# ESP32S31_RADIO register map
Vendor: Espressif; Series: ESP32-S31; File version: 3.52
Registers are 32-bit, read-write, no defined reset value unless marked. A register's access mark holds for its fields unless they carry their own. Offsets are from the block's base; [hi:lo] are bit positions; {n}, {i} and the like mark numbered series; 'fields as' and 'values as' point back to an identical list.

## PHY_I2C_COMMAND_RAM — Official S31 reg_base.h names this aperture DR_REG_I2C_ANA_MST_MEM_BASE. The complete blob establishes its forty-five-entry command layout and the population order in phy_i2c_master_cmd_mem_init. Complete phy_i2c_check independently names ten logical banks, their block IDs, selected host and finite register-index ranges.
Base 0x2010FC00
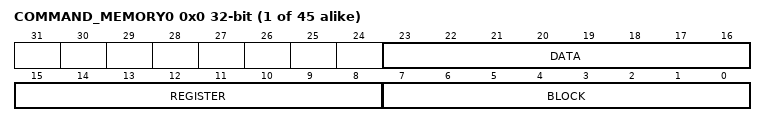
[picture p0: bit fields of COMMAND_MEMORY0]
{0x0+4i} COMMAND_MEMORY{i} (i=0..44) wo — Project-assigned name. One PHY-I2C master command-memory entry; the public header proves the containing memory aperture while the complete blob proves this word layout.
  [23:16] DATA — Project-assigned name.
  [15:8] REGISTER — Project-assigned name.
  [7:0] BLOCK — Project-assigned name. Logical PHY-I2C block ID. The bank host and valid half-open register-index ranges are: SAR1 host 0 [0,7), ULP host 1 [0,11), RFPLL host 1 [0,22), RFPLL_SDM host 1 [0,7), BBPLL host 0 [0,11), BBTOP host 1 [0,57), PERIF host 0 [0,13), BIAS host 1 [0,4), TXRF host 1 [1,22), DIG_REG host 0 [0,15).
    16=SAR1; 97=ULP; 98=RFPLL; 99=RFPLL_SDM; 102=BBPLL; 103=BBTOP; 105=PERIF; 106=BIAS; 107=TXRF; 109=DIG_REG

## WIFI_PHY_RATE_ORACLE — Wi-Fi-owned PHY words: the noise-floor measurement read by Wi-Fi link policy and the low-rate receive gate of Wi-Fi rate control and 11b long-range RX. Only Wi-Fi touches these words: no PHY registration, calibration or tracking body and no Bluetooth or IEEE 802.15.4 body accesses them, so they belong to the Wi-Fi partition rather than the shared radio PHY. They share the radio-core base with the PHY oracles.
Base 0x20100000
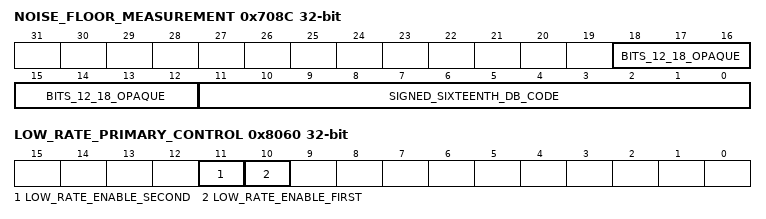
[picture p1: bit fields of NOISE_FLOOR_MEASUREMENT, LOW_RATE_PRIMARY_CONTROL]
0x708C NOISE_FLOOR_MEASUREMENT ro — Project-assigned name. Complete phy_read_hw_noisefloor reads this word once, sign-extends the low twelve-bit two's-complement value and divides it arithmetically by four to produce its quarter-dB result; it consumes no higher bits. The librftest saturation probes read bits 18:12. Open rev0 HIL read a stable -92 dBm whole-unit result through the complete ROM plus wDev transform.
  [18:12] BITS_12_18_OPAQUE — Opaque: meaning not established. Seven-bit receive status field. Complete librftest get_rfrx_sat counts how many of one hundred reads have the value 49 and returns that count as its RF receive saturation result; phy_rx_sat_test samples it after forcing receive gain. Neither body assigns a unit to the value.
  [11:0] SIGNED_SIXTEENTH_DB_CODE — Project-assigned name. Signed twelve-bit noise-floor measurement in sixteenth-dB units. The complete ROM arithmetic shift produces quarter-dB and libpp[wdev.o]::wDev_GetNoiseFloor applies rounded division by four once more before retaining a signed byte; open rev0 HIL observed -92 dBm.
0x8060 LOW_RATE_PRIMARY_CONTROL — Project-assigned name. Complete phy_enable_low_rate sets bits 10 and 11 through separate fresh-read RMW edges; complete phy_disable_low_rate clears them in the same order; complete phy_rx11blr_cfg replaces both with its caller low bit.
  [11] LOW_RATE_ENABLE_SECOND — Project-assigned name. Second independently updated low-rate enable bit.
  [10] LOW_RATE_ENABLE_FIRST — Project-assigned name. First independently updated low-rate enable bit.
0x807C LOW_RATE_SECONDARY_CONTROL — Project-assigned name. Third and final fresh-read RMW in the complete low-rate leaves and phy_rx11blr_cfg.
  [11] LOW_RATE_ENABLE — Project-assigned name. Set by complete phy_enable_low_rate and cleared by complete phy_disable_low_rate.

## PHY_IQ_ESTIMATOR_ORACLE — DC/IQ estimator configuration, signed result and activity registers recovered from complete S31 rev0 ROM bodies and the complete pinned phy_check_rx_sat blob leaf. Unknown electrical roles remain explicit.
Base 0x20100000
0x44C ESTIMATOR_CONFIG — Project-assigned name. Complete phy_iq_est_enable replaces bits 27:26 with encoding one before each measurement.
  [27:26] BITS_26_27_OPAQUE — Opaque: meaning not established. Two-bit field set to encoding one by phy_iq_est_enable.
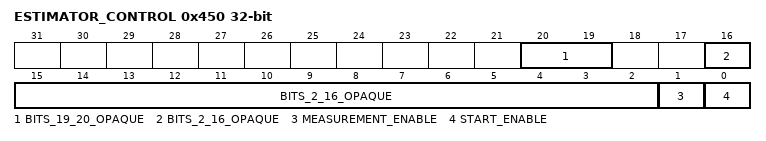
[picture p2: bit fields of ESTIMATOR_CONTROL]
0x450 ESTIMATOR_CONTROL — Project-assigned name. Complete phy_iq_est_enable publishes the caller control word and starts both measurement phases; complete phy_iq_est_disable clears them in reverse order around a one-microsecond delay.
  [20:19] BITS_19_20_OPAQUE — Opaque: meaning not established. Complete phy_iq_est_enable replaces the field with encoding two.
  [16:2] BITS_2_16_OPAQUE — Opaque: meaning not established. Fifteen-bit caller value shifted left by two.
  [1] MEASUREMENT_ENABLE — Project-assigned name.
  [0] START_ENABLE — Project-assigned name.
0x454 SIGNAL_POWER_SUM_I ro — Project-assigned name. Signed result consumed by complete phy_rxiq_get_mis and phy_get_rx_sig_pwr.
  [31:0] VALUE — Project-assigned name. Complete signed estimator result.
0x458 SIGNAL_POWER_DIFFERENCE_I ro — Project-assigned name. Signed result consumed by complete phy_rxiq_get_mis and phy_get_rx_sig_pwr.
  fields as SIGNAL_POWER_SUM_I
0x45C SIGNAL_POWER_DIFFERENCE_Q ro — Project-assigned name. Signed result consumed by complete phy_rxiq_get_mis and phy_get_rx_sig_pwr.
  fields as SIGNAL_POWER_SUM_I
0x460 SIGNAL_POWER_SUM_Q ro — Project-assigned name. Signed result consumed by complete phy_rxiq_get_mis and phy_get_rx_sig_pwr.
  fields as SIGNAL_POWER_SUM_I
0x464 DC_I_ACCUMULATOR ro — Project-assigned name. First signed accumulator read by complete phy_dc_iq_est.
  [31:0] VALUE — Project-assigned name. Complete signed accumulator value.
0x468 DC_Q_ACCUMULATOR ro — Project-assigned name. Second signed accumulator read by complete phy_dc_iq_est.
  fields as DC_I_ACCUMULATOR
0x46C POWER_ACCUMULATOR ro — Project-assigned name. Signed power accumulator consumed by complete phy_dc_iq_est, phy_rxiq_get_mis and phy_set_rx_gain_cal_iq.
  fields as DC_I_ACCUMULATOR
0x47C ESTIMATOR_READY_STATUS ro — Project-assigned name. Complete phy_iq_est_enable tests bit 16 before leaving its readiness loop.
  [16] READY — Project-assigned name.
0x8D0 ESTIMATOR_ACTIVITY_STATUS ro — Project-assigned name. Complete phy_iq_est_enable counts nonzero bits 21:20 while waiting; complete phy_check_rx_sat samples the same field exactly 100 times.
  [21:20] BITS_20_21_OPAQUE — Opaque: meaning not established. Nonzero is treated as IQ-estimator activity and as an RX-saturation sample.
